AUTOSAR XML (schema 00050)
package /Components
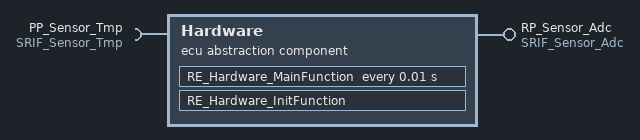
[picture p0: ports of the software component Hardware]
  ecu abstraction sw component type Hardware
    require port PP_Sensor_Tmp: nonqueued-receiver-com-spec{data-element=Tmp_Value, init-value=0}, required-interface=SRIF_Sensor_Tmp
    provide port RP_Sensor_Adc: nonqueued-sender-com-spec{data-element=Adc_Value, init-value=0}, provided-interface=SRIF_Sensor_Adc
    behavior untitled_IB: handle-termination-and-restart=NO-SUPPORT
      static-memorys:
        data rtTmp_Value: category=VALUE, sw-calibration-access=READ-ONLY, type=Double
      timing event Event: start-on-event=RE_Hardware_MainFunction, period=0.01
      runnable RE_Hardware_InitFunction
      runnable RE_Hardware_MainFunction
        data-read-access:
          access IN_PP_Sensor_Tmp_Tmp_Value: accessed-variable=PP_Sensor_Tmp.Tmp_Value
        data-write-access:
          access OUT_RP_Sensor_Adc_Adc_Value: accessed-variable=RP_Sensor_Adc.Adc_Value
